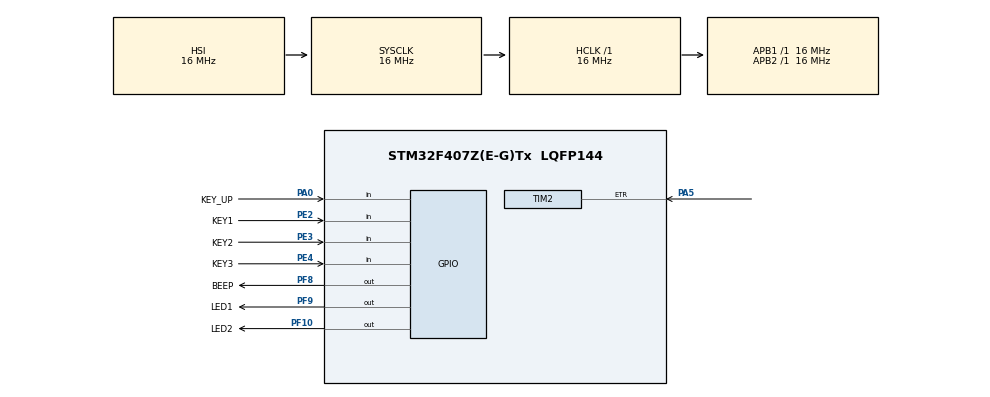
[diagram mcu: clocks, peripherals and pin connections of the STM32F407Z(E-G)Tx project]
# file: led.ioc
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Mcu.Family=STM32F4
Mcu.Name=STM32F407Z(E-G)Tx
Mcu.Package=LQFP144
NVIC.PriorityGroup=NVIC_PRIORITYGROUP_4
NVIC.TIM2_IRQn=true\:0\:0\:false\:false\:true\:true\:true
PA0-WKUP.GPIO_Label=KEY_UP
PA0-WKUP.GPIO_PuPd=GPIO_PULLDOWN
PA0-WKUP.Signal=GPIO_Input
PA5.Signal=S_TIM2_CH1_ETR
PE2.GPIO_Label=KEY1
PE2.GPIO_PuPd=GPIO_PULLUP
PE2.Signal=GPIO_Input
PE3.GPIO_Label=KEY2
PE3.GPIO_PuPd=GPIO_PULLUP
PE3.Signal=GPIO_Input
PE4.GPIO_Label=KEY3
PE4.GPIO_PuPd=GPIO_PULLUP
PE4.Signal=GPIO_Input
PF10.GPIO_Label=LED2
PF10.Signal=GPIO_Output
PF8.GPIO_Label=BEEP
PF8.Signal=GPIO_Output
PF9.GPIO_Label=LED1
PF9.Signal=GPIO_Output
ProjectManager.HeapSize=0x200
ProjectManager.StackSize=0x400
ProjectManager.TargetToolchain=EWARM V8
RCC.AHBFreq_Value=16000000
RCC.APB1Freq_Value=16000000
RCC.APB2Freq_Value=16000000
RCC.CortexFreq_Value=16000000
RCC.HSE_VALUE=25000000
RCC.HSI_VALUE=16000000
RCC.LSE_VALUE=32768
RCC.SYSCLKFreq_VALUE=16000000
RCC.VCOOutputFreq_Value=192000000
SH.S_TIM2_CH1_ETR.0=TIM2_ETR,ClockSourceETR_Mode2
TIM2.Period=999
TIM2.Prescaler=16
board=custom

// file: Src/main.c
/* USER CODE BEGIN Header */
/**
  ******************************************************************************
  * @file           : main.c
  * @brief          : Main program body
  ******************************************************************************
  * @attention
  *
  * <h2><center>&copy; Copyright (c) 2020 STMicroelectronics.
  * All rights reserved.</center></h2>
  *
  * This software component is licensed by ST under BSD 3-Clause license,
  * the "License"; You may not use this file except in compliance with the
  * License. You may obtain a copy of the License at:
  *                        opensource.org/licenses/BSD-3-Clause
  *
  ******************************************************************************
  */
/* USER CODE END Header */

#include "main.h"
#include "tim.h"
#include "gpio.h"

/* USER CODE BEGIN Includes */
#include "task.h"
/* USER CODE END Includes */

void SystemClock_Config(void);

int main(void)
{

  /* MCU Configuration--------------------------------------------------------*/

  /* Reset of all peripherals, Initializes the Flash interface and the Systick. */
  HAL_Init();

  /* Configure the system clock */
  SystemClock_Config();

  /* Initialize all configured peripherals */
  MX_GPIO_Init();
  MX_TIM2_Init();
  /* USER CODE BEGIN 2 */
  task_init();
  /* USER CODE END 2 */

  /* Infinite loop */
  /* USER CODE BEGIN WHILE */
  while (1)
  {
    task_exec();
    /* USER CODE END WHILE */

    /* USER CODE BEGIN 3 */
    HAL_Delay(1);
  }
  /* USER CODE END 3 */
}

void SystemClock_Config(void)
{
  RCC_OscInitTypeDef RCC_OscInitStruct = {0};
  RCC_ClkInitTypeDef RCC_ClkInitStruct = {0};

  /** Configure the main internal regulator output voltage
  */
  __HAL_RCC_PWR_CLK_ENABLE();
  __HAL_PWR_VOLTAGESCALING_CONFIG(PWR_REGULATOR_VOLTAGE_SCALE1);
  /** Initializes the CPU, AHB and APB busses clocks
  */
  RCC_OscInitStruct.OscillatorType = RCC_OSCILLATORTYPE_HSI;
  RCC_OscInitStruct.HSIState = RCC_HSI_ON;
  RCC_OscInitStruct.HSICalibrationValue = RCC_HSICALIBRATION_DEFAULT;
  RCC_OscInitStruct.PLL.PLLState = RCC_PLL_NONE;
  if (HAL_RCC_OscConfig(&RCC_OscInitStruct) != HAL_OK)
  {
    Error_Handler();
  }
  /** Initializes the CPU, AHB and APB busses clocks
  */
  RCC_ClkInitStruct.ClockType = RCC_CLOCKTYPE_HCLK|RCC_CLOCKTYPE_SYSCLK
                              |RCC_CLOCKTYPE_PCLK1|RCC_CLOCKTYPE_PCLK2;
  RCC_ClkInitStruct.SYSCLKSource = RCC_SYSCLKSOURCE_HSI;
  RCC_ClkInitStruct.AHBCLKDivider = RCC_SYSCLK_DIV1;
  RCC_ClkInitStruct.APB1CLKDivider = RCC_HCLK_DIV1;
  RCC_ClkInitStruct.APB2CLKDivider = RCC_HCLK_DIV1;

  if (HAL_RCC_ClockConfig(&RCC_ClkInitStruct, FLASH_LATENCY_0) != HAL_OK)
  {
    Error_Handler();
  }
}

void Error_Handler(void)
{
}

/************************ (C) COPYRIGHT STMicroelectronics *****END OF FILE****/
